AUTOSAR XML (schema 4-2-2)
package /Components
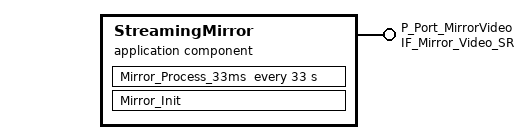
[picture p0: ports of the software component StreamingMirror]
  application sw component type StreamingMirror
    provide port P_Port_MirrorVideo: provided-interface=IF_Mirror_Video_SR
    behavior StreamingMirror_InternalBehavior
      init event Mirror_Init_Event: start-on-event=Mirror_Init
      timing event Mirror_Frame_Tick: start-on-event=Mirror_Process_33ms, period=33
      runnable Mirror_Init
        parameter access PA_Read_Default_Channel: accessed-parameter=P_Port_MirrorVideo.Channel_Id
      runnable Mirror_Process_33ms: minimum-start-interval=33
        data-send-points:
          access VA_Send_Mirror_Frame: accessed-variable=P_Port_MirrorVideo.Mirror_Frame
          access VA_Send_Channel_Id: accessed-variable=P_Port_MirrorVideo.Channel_Id
          access VA_Send_Timestamp: accessed-variable=P_Port_MirrorVideo.Timestamp
        parameter access PA_Read_Current_Channel: accessed-parameter=P_Port_MirrorVideo.Channel_Id
